# STM32H747ZIY6@M7 register map
File version: 1.0
Registers are 32-bit, access not given, reset 0x0 unless marked. A register's access mark holds for its fields unless they carry their own. Offsets are from the block's base; [hi:lo] are bit positions; {n}, {i} and the like mark numbered series; 'fields as' and 'values as' point back to an identical list.

## MDMA
Base 0x52000000
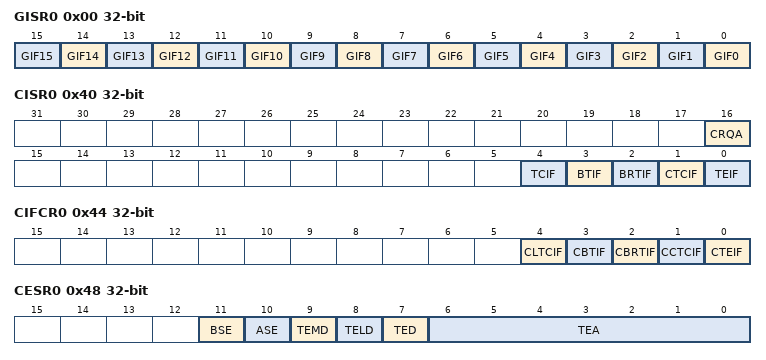
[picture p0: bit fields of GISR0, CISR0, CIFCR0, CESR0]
0x00 GISR0
  [n] GIF{n} (n=0..15)
0x40 CISR0
  [16] CRQA, [4] TCIF, [3] BTIF, [2] BRTIF, [1] CTCIF, [0] TEIF
0x44 CIFCR0
  [4] CLTCIF, [3] CBTIF, [2] CBRTIF, [1] CCTCIF, [0] CTEIF
0x48 CESR0
  [11] BSE, [10] ASE, [9] TEMD, [8] TELD, [7] TED, [6:0] TEA
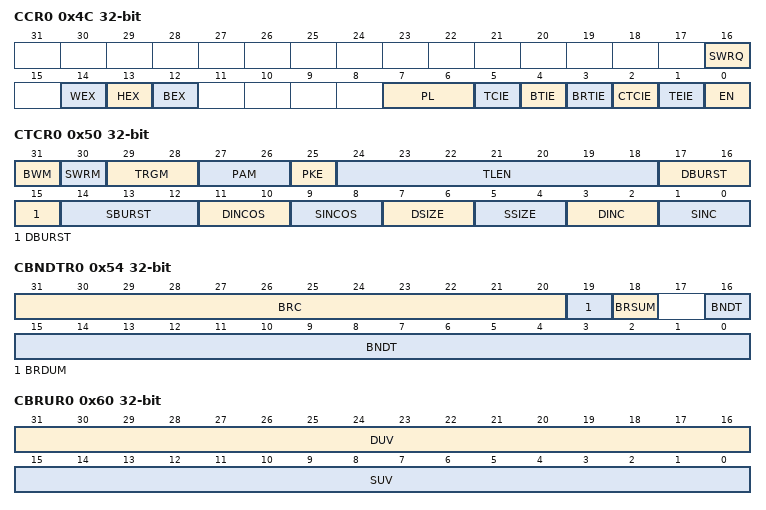
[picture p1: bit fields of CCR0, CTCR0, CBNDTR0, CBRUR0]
0x4C CCR0
  [16] SWRQ, [14] WEX, [13] HEX, [12] BEX, [7:6] PL, [5] TCIE, [4] BTIE, [3] BRTIE, [2] CTCIE, [1] TEIE, [0] EN
0x50 CTCR0
  [31] BWM, [30] SWRM, [29:28] TRGM, [27:26] PAM, [25] PKE, [24:18] TLEN, [17:15] DBURST, [14:12] SBURST, [11:10] DINCOS, [9:8] SINCOS, [7:6] DSIZE, [5:4] SSIZE, [3:2] DINC, [1:0] SINC
0x54 CBNDTR0
  [31:20] BRC, [19] BRDUM, [18] BRSUM, [16:0] BNDT
0x58 CSAR0
  [31:0] SAR
0x5C CDAR0
  [31:0] DAR
0x60 CBRUR0
  [31:16] DUV, [15:0] SUV
0x64 CLAR0
  [31:0] LAR
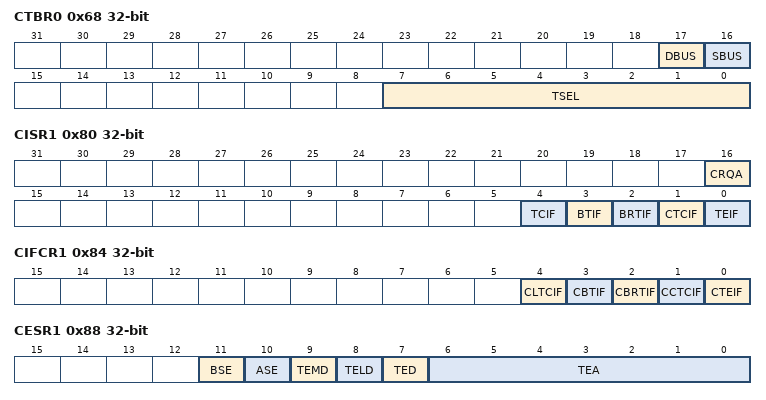
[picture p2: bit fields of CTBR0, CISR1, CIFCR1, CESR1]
0x68 CTBR0
  [17] DBUS, [16] SBUS, [7:0] TSEL
0x70 CMAR0
  [31:0] MAR
0x74 CMDR0
  [31:0] MDR
0x80 CISR1
  [16] CRQA, [4] TCIF, [3] BTIF, [2] BRTIF, [1] CTCIF, [0] TEIF
0x84 CIFCR1
  [4] CLTCIF, [3] CBTIF, [2] CBRTIF, [1] CCTCIF, [0] CTEIF
0x88 CESR1
  [11] BSE, [10] ASE, [9] TEMD, [8] TELD, [7] TED, [6:0] TEA
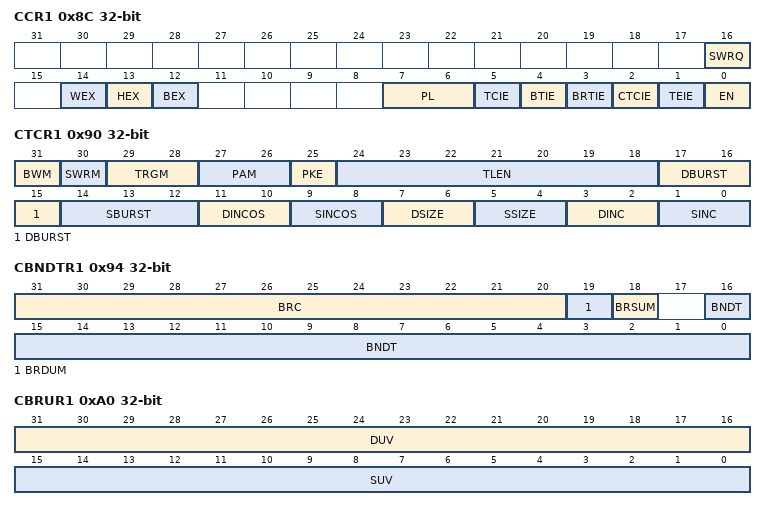
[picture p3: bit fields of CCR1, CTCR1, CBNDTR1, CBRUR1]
0x8C CCR1
  fields as CCR0
0x90 CTCR1
  fields as CTCR0
0x94 CBNDTR1
  [31:20] BRC, [19] BRDUM, [18] BRSUM, [16:0] BNDT
0x98 CSAR1
  [31:0] SAR
0x9C CDAR1
  [31:0] DAR
0xA0 CBRUR1
  [31:16] DUV, [15:0] SUV
0xA4 CLAR1
  [31:0] LAR
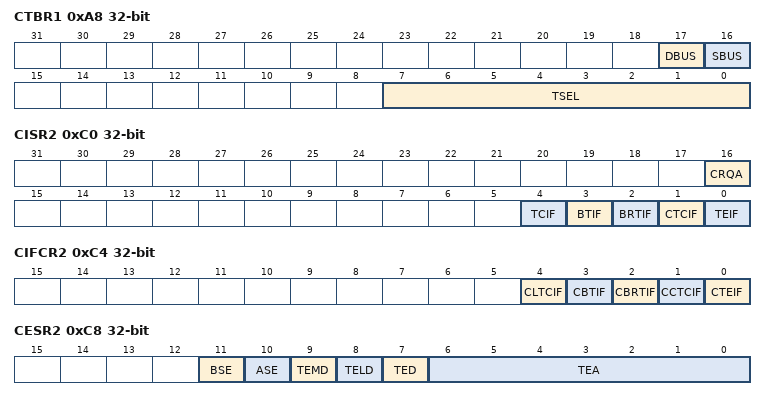
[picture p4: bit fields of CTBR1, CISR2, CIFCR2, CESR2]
0xA8 CTBR1
  [17] DBUS, [16] SBUS, [7:0] TSEL
0xB0 CMAR1
  [31:0] MAR
0xB4 CMDR1
  [31:0] MDR
0xC0 CISR2
  [16] CRQA, [4] TCIF, [3] BTIF, [2] BRTIF, [1] CTCIF, [0] TEIF
0xC4 CIFCR2
  [4] CLTCIF, [3] CBTIF, [2] CBRTIF, [1] CCTCIF, [0] CTEIF
0xC8 CESR2
  [11] BSE, [10] ASE, [9] TEMD, [8] TELD, [7] TED, [6:0] TEA
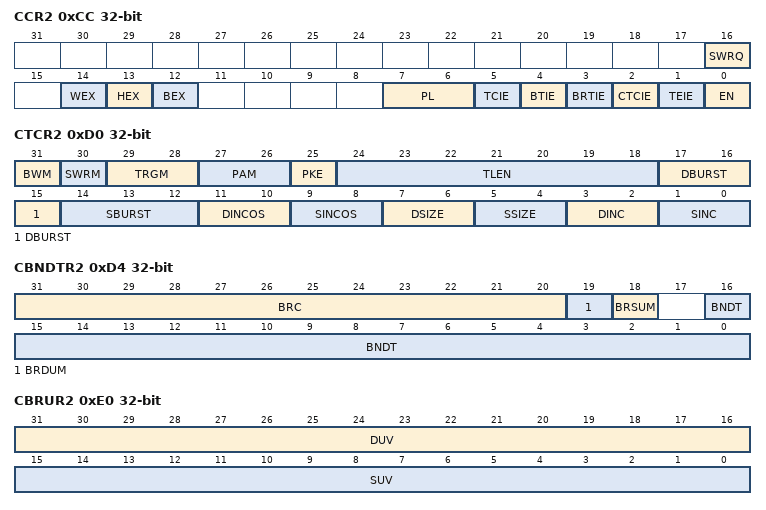
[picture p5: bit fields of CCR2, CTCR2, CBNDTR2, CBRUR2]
0xCC CCR2
  fields as CCR0
0xD0 CTCR2
  fields as CTCR0
0xD4 CBNDTR2
  [31:20] BRC, [19] BRDUM, [18] BRSUM, [16:0] BNDT
0xD8 CSAR2
  [31:0] SAR
0xDC CDAR2
  [31:0] DAR
0xE0 CBRUR2
  [31:16] DUV, [15:0] SUV
0xE4 CLAR2
  [31:0] LAR
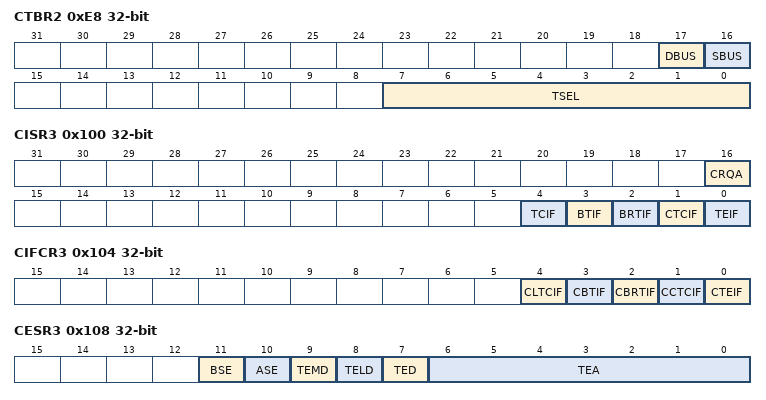
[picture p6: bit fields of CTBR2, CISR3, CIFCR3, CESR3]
0xE8 CTBR2
  [17] DBUS, [16] SBUS, [7:0] TSEL
0xF0 CMAR2
  [31:0] MAR
0xF4 CMDR2
  [31:0] MDR
0x100 CISR3
  [16] CRQA, [4] TCIF, [3] BTIF, [2] BRTIF, [1] CTCIF, [0] TEIF
0x104 CIFCR3
  [4] CLTCIF, [3] CBTIF, [2] CBRTIF, [1] CCTCIF, [0] CTEIF
0x108 CESR3
  [11] BSE, [10] ASE, [9] TEMD, [8] TELD, [7] TED, [6:0] TEA
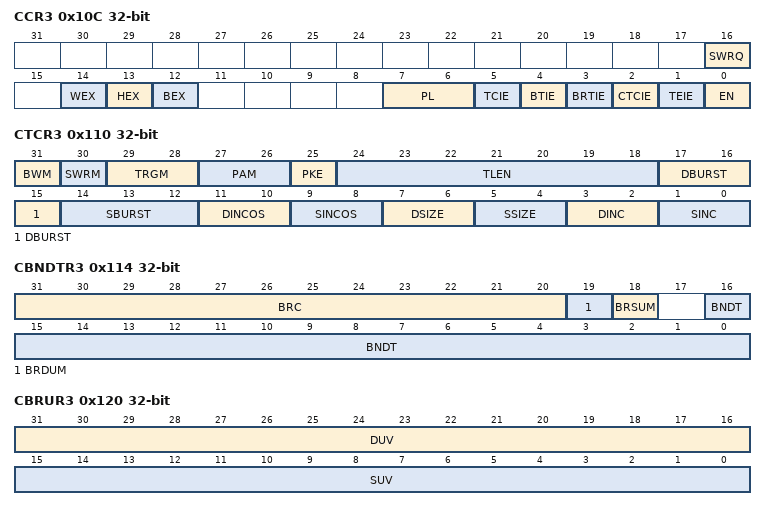
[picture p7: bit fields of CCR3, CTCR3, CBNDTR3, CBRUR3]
0x10C CCR3
  fields as CCR0
0x110 CTCR3
  fields as CTCR0
0x114 CBNDTR3
  [31:20] BRC, [19] BRDUM, [18] BRSUM, [16:0] BNDT
0x118 CSAR3
  [31:0] SAR
0x11C CDAR3
  [31:0] DAR
0x120 CBRUR3
  [31:16] DUV, [15:0] SUV
0x124 CLAR3
  [31:0] LAR
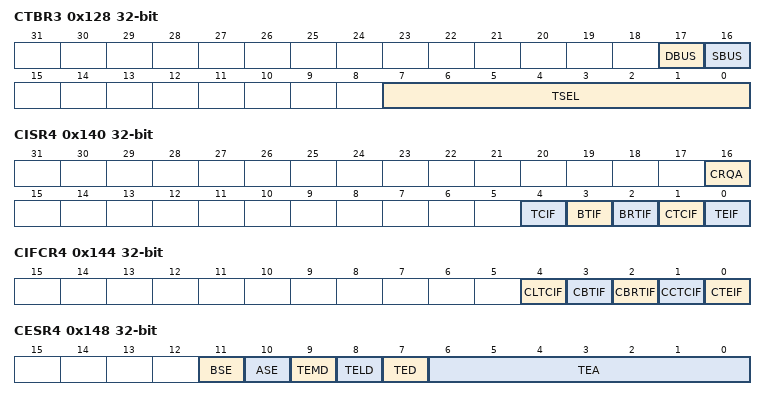
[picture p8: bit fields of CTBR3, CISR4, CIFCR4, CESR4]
0x128 CTBR3
  [17] DBUS, [16] SBUS, [7:0] TSEL
0x130 CMAR3
  [31:0] MAR
0x134 CMDR3
  [31:0] MDR
0x140 CISR4
  [16] CRQA, [4] TCIF, [3] BTIF, [2] BRTIF, [1] CTCIF, [0] TEIF
0x144 CIFCR4
  [4] CLTCIF, [3] CBTIF, [2] CBRTIF, [1] CCTCIF, [0] CTEIF
0x148 CESR4
  [11] BSE, [10] ASE, [9] TEMD, [8] TELD, [7] TED, [6:0] TEA
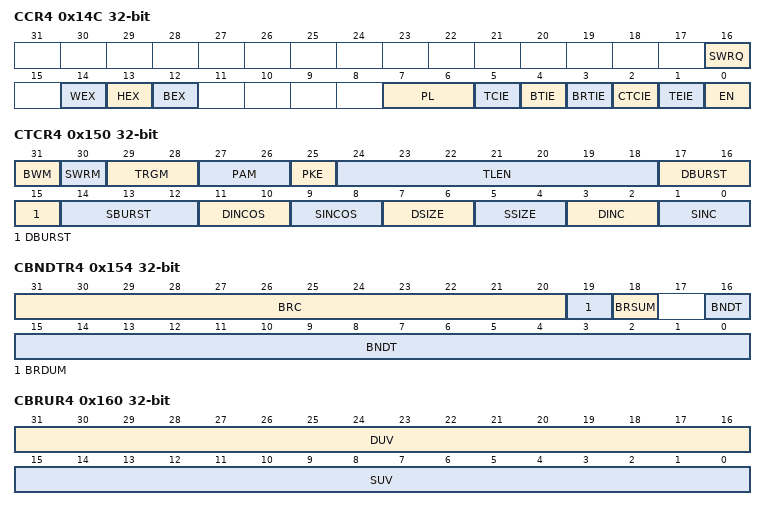
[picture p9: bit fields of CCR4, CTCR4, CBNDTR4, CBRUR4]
0x14C CCR4
  fields as CCR0
0x150 CTCR4
  fields as CTCR0
0x154 CBNDTR4
  [31:20] BRC, [19] BRDUM, [18] BRSUM, [16:0] BNDT
0x158 CSAR4
  [31:0] SAR
0x15C CDAR4
  [31:0] DAR
0x160 CBRUR4
  [31:16] DUV, [15:0] SUV
0x164 CLAR4
  [31:0] LAR
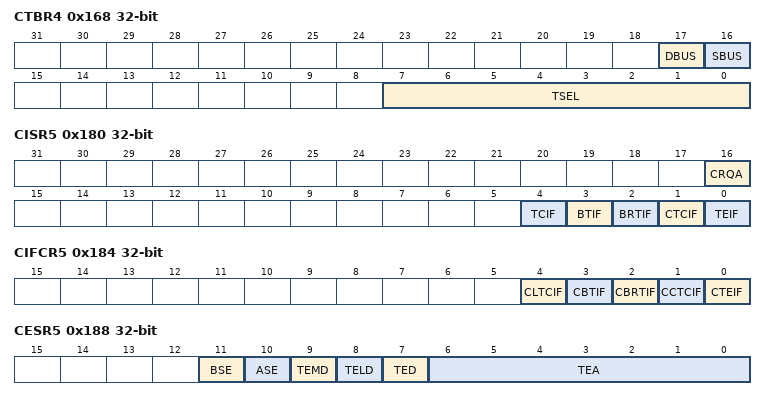
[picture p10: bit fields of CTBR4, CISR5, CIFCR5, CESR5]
0x168 CTBR4
  [17] DBUS, [16] SBUS, [7:0] TSEL
0x170 CMAR4
  [31:0] MAR
0x174 CMDR4
  [31:0] MDR
0x180 CISR5
  [16] CRQA, [4] TCIF, [3] BTIF, [2] BRTIF, [1] CTCIF, [0] TEIF
0x184 CIFCR5
  [4] CLTCIF, [3] CBTIF, [2] CBRTIF, [1] CCTCIF, [0] CTEIF
0x188 CESR5
  [11] BSE, [10] ASE, [9] TEMD, [8] TELD, [7] TED, [6:0] TEA
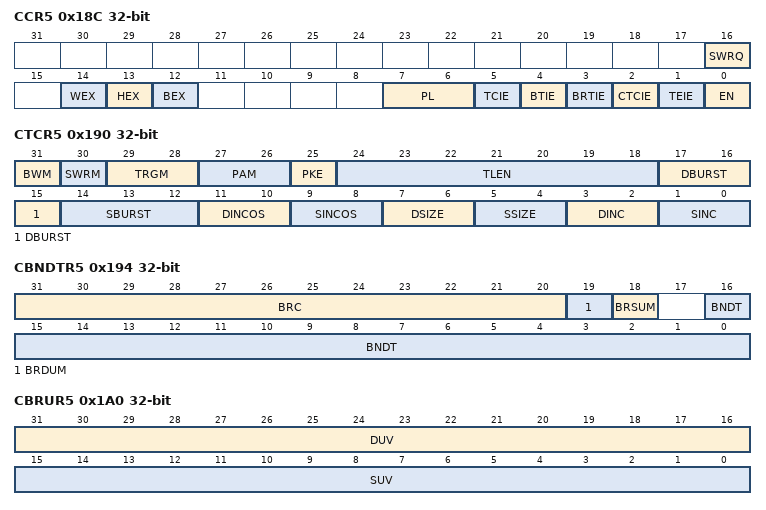
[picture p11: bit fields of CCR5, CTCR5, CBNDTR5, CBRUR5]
0x18C CCR5
  fields as CCR0
0x190 CTCR5
  fields as CTCR0
0x194 CBNDTR5
  [31:20] BRC, [19] BRDUM, [18] BRSUM, [16:0] BNDT
0x198 CSAR5
  [31:0] SAR
0x19C CDAR5
  [31:0] DAR
0x1A0 CBRUR5
  [31:16] DUV, [15:0] SUV
0x1A4 CLAR5
  [31:0] LAR
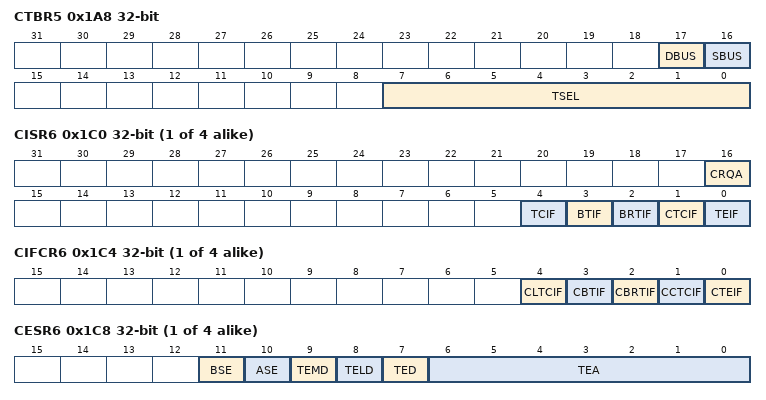
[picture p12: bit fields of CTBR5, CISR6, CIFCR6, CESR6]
0x1A8 CTBR5
  [17] DBUS, [16] SBUS, [7:0] TSEL
0x1B0 CMAR5
  [31:0] MAR
0x1B4 CMDR5
  [31:0] MDR
{0x40+0x40*i} CISR{i} (i=6..9)
  [16] CRQA, [4] TCIF, [3] BTIF, [2] BRTIF, [1] CTCIF, [0] TEIF
{0x44+0x40*i} CIFCR{i} (i=6..9)
  [4] CLTCIF, [3] CBTIF, [2] CBRTIF, [1] CCTCIF, [0] CTEIF
{0x48+0x40*i} CESR{i} (i=6..9)
  [11] BSE, [10] ASE, [9] TEMD, [8] TELD, [7] TED, [6:0] TEA
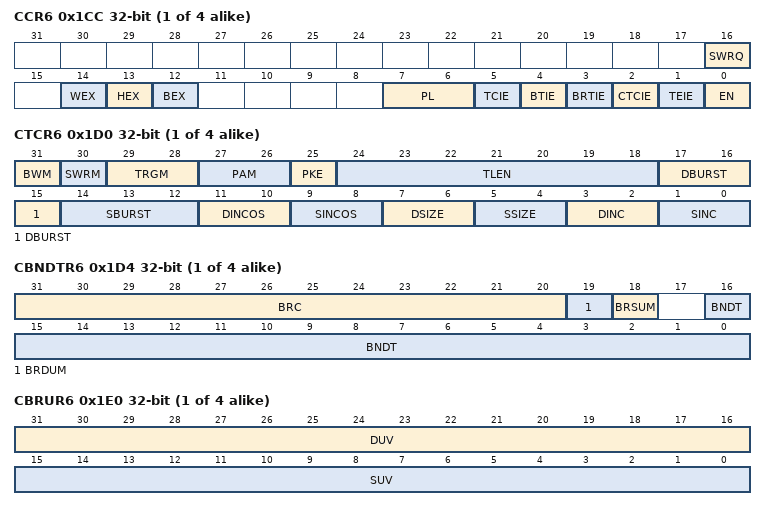
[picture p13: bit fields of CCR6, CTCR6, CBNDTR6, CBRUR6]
{0x4C+0x40*i} CCR{i} (i=6..9)
  fields as CCR0
{0x50+0x40*i} CTCR{i} (i=6..9)
  fields as CTCR0
{0x54+0x40*i} CBNDTR{i} (i=6..9)
  [31:20] BRC, [19] BRDUM, [18] BRSUM, [16:0] BNDT
{0x58+0x40*i} CSAR{i} (i=6..9)
  [31:0] SAR
{0x5C+0x40*i} CDAR{i} (i=6..9)
  [31:0] DAR
{0x60+0x40*i} CBRUR{i} (i=6..9)
  [31:16] DUV, [15:0] SUV
{0x64+0x40*i} CLAR{i} (i=6..9)
  [31:0] LAR
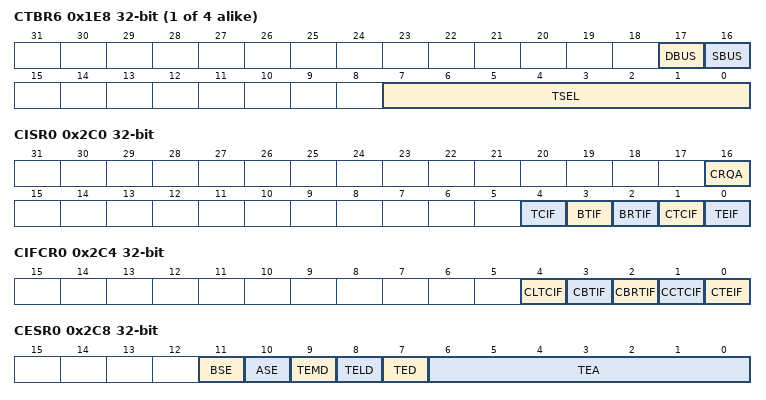
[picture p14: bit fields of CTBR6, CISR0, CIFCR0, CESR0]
{0x68+0x40*i} CTBR{i} (i=6..9)
  [17] DBUS, [16] SBUS, [7:0] TSEL
{0x70+0x40*i} CMAR{i} (i=6..9)
  [31:0] MAR
{0x74+0x40*i} CMDR{i} (i=6..9)
  [31:0] MDR
0x2C0 CISR0
  [16] CRQA, [4] TCIF, [3] BTIF, [2] BRTIF, [1] CTCIF, [0] TEIF
0x2C4 CIFCR0
  [4] CLTCIF, [3] CBTIF, [2] CBRTIF, [1] CCTCIF, [0] CTEIF
0x2C8 CESR0
  [11] BSE, [10] ASE, [9] TEMD, [8] TELD, [7] TED, [6:0] TEA
0x2CC CCR0
  fields as CCR0
0x2D0 CTCR0
  fields as CTCR0
0x2D4 CBNDTR0
  [31:20] BRC, [19] BRDUM, [18] BRSUM, [16:0] BNDT
0x2D8 CSAR0
  [31:0] SAR
0x2DC CDAR0
  [31:0] DAR
0x2E0 CBRUR0
  [31:16] DUV, [15:0] SUV
0x2E4 CLAR0
  [31:0] LAR
0x2E8 CTBR0
  [17] DBUS, [16] SBUS, [7:0] TSEL
0x2F0 CMAR0
  [31:0] MAR
0x2F4 CMDR0
  [31:0] MDR
0x300 CISR1
  [16] CRQA, [4] TCIF, [3] BTIF, [2] BRTIF, [1] CTCIF, [0] TEIF
0x304 CIFCR1
  [4] CLTCIF, [3] CBTIF, [2] CBRTIF, [1] CCTCIF, [0] CTEIF
0x308 CESR1
  [11] BSE, [10] ASE, [9] TEMD, [8] TELD, [7] TED, [6:0] TEA
0x30C CCR1
  fields as CCR0
0x310 CTCR1
  fields as CTCR0
0x314 CBNDTR1
  [31:20] BRC, [19] BRDUM, [18] BRSUM, [16:0] BNDT
0x318 CSAR1
  [31:0] SAR
0x31C CDAR1
  [31:0] DAR
0x320 CBRUR1
  [31:16] DUV, [15:0] SUV
0x324 CLAR1
  [31:0] LAR
0x328 CTBR1
  [17] DBUS, [16] SBUS, [7:0] TSEL
0x330 CMAR1
  [31:0] MAR
0x334 CMDR1
  [31:0] MDR
0x340 CISR2
  [16] CRQA, [4] TCIF, [3] BTIF, [2] BRTIF, [1] CTCIF, [0] TEIF
0x344 CIFCR2
  [4] CLTCIF, [3] CBTIF, [2] CBRTIF, [1] CCTCIF, [0] CTEIF
0x348 CESR2
  [11] BSE, [10] ASE, [9] TEMD, [8] TELD, [7] TED, [6:0] TEA
0x34C CCR2
  fields as CCR0
0x350 CTCR2
  fields as CTCR0
0x354 CBNDTR2
  [31:20] BRC, [19] BRDUM, [18] BRSUM, [16:0] BNDT
0x358 CSAR2
  [31:0] SAR
0x35C CDAR2
  [31:0] DAR
0x360 CBRUR2
  [31:16] DUV, [15:0] SUV
0x364 CLAR2
  [31:0] LAR
0x368 CTBR2
  [17] DBUS, [16] SBUS, [7:0] TSEL
0x370 CMAR2
  [31:0] MAR
0x374 CMDR2
  [31:0] MDR
0x380 CISR3
  [16] CRQA, [4] TCIF, [3] BTIF, [2] BRTIF, [1] CTCIF, [0] TEIF
0x384 CIFCR3
  [4] CLTCIF, [3] CBTIF, [2] CBRTIF, [1] CCTCIF, [0] CTEIF
0x388 CESR3
  [11] BSE, [10] ASE, [9] TEMD, [8] TELD, [7] TED, [6:0] TEA
0x38C CCR3
  fields as CCR0
0x390 CTCR3
  fields as CTCR0
0x394 CBNDTR3
  [31:20] BRC, [19] BRDUM, [18] BRSUM, [16:0] BNDT
0x398 CSAR3
  [31:0] SAR
0x39C CDAR3
  [31:0] DAR
0x3A0 CBRUR3
  [31:16] DUV, [15:0] SUV
0x3A4 CLAR3
  [31:0] LAR
0x3A8 CTBR3
  [17] DBUS, [16] SBUS, [7:0] TSEL
0x3B0 CMAR3
  [31:0] MAR
0x3B4 CMDR3
  [31:0] MDR
0x3C0 CISR4
  [16] CRQA, [4] TCIF, [3] BTIF, [2] BRTIF, [1] CTCIF, [0] TEIF
0x3C4 CIFCR4
  [4] CLTCIF, [3] CBTIF, [2] CBRTIF, [1] CCTCIF, [0] CTEIF
0x3C8 CESR4
  [11] BSE, [10] ASE, [9] TEMD, [8] TELD, [7] TED, [6:0] TEA
0x3CC CCR4
  fields as CCR0
0x3D0 CTCR4
  fields as CTCR0
0x3D4 CBNDTR4
  [31:20] BRC, [19] BRDUM, [18] BRSUM, [16:0] BNDT
0x3D8 CSAR4
  [31:0] SAR
0x3DC CDAR4
  [31:0] DAR
0x3E0 CBRUR4
  [31:16] DUV, [15:0] SUV
0x3E4 CLAR4
  [31:0] LAR
0x3E8 CTBR4
  [17] DBUS, [16] SBUS, [7:0] TSEL
0x3F0 CMAR4
  [31:0] MAR
0x3F4 CMDR4
  [31:0] MDR
0x400 CISR5
  [16] CRQA, [4] TCIF, [3] BTIF, [2] BRTIF, [1] CTCIF, [0] TEIF
0x404 CIFCR5
  [4] CLTCIF, [3] CBTIF, [2] CBRTIF, [1] CCTCIF, [0] CTEIF
0x408 CESR5
  [11] BSE, [10] ASE, [9] TEMD, [8] TELD, [7] TED, [6:0] TEA
0x40C CCR5
  fields as CCR0
0x410 CTCR5
  fields as CTCR0
0x414 CBNDTR5
  [31:20] BRC, [19] BRDUM, [18] BRSUM, [16:0] BNDT
0x418 CSAR5
  [31:0] SAR
0x41C CDAR5
  [31:0] DAR
0x420 CBRUR5
  [31:16] DUV, [15:0] SUV
0x424 CLAR5
  [31:0] LAR
0x428 CTBR5
  [17] DBUS, [16] SBUS, [7:0] TSEL
0x430 CMAR5
  [31:0] MAR
0x434 CMDR5
  [31:0] MDR
